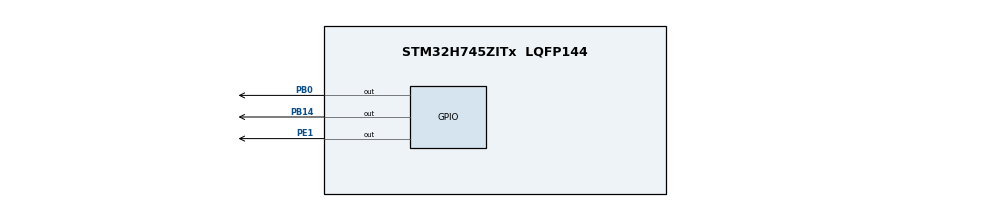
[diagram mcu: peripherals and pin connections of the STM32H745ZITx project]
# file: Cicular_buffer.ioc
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CortexM4.IPs=BDMA,CORTEX_M4\:I,DEBUG,DMA,FATFS_M4\:I,FREERTOS_M4\:I,IWDG2\:I,MDMA,NVIC2\:I,OPENAMP_M4\:I,PDM2PCM_M4\:I,PWR,RCC,RESMGR_UTILITY,SYS_M4\:I,USB_DEVICE_M4\:I,USB_HOST_M4\:I,VREFBUF,WWDG2\:I
CortexM7.IPs=BDMA\:I,CORTEX_M7\:I,DEBUG\:I,DMA\:I,FATFS_M7\:I,FREERTOS_M7\:I,IWDG1\:I,MDMA\:I,NVIC1\:I,OPENAMP_M7\:I,PDM2PCM_M7\:I,PWR\:I,RCC\:I,RESMGR_UTILITY\:I,SYS\:I,USB_DEVICE_M7\:I,USB_HOST_M7\:I,VREFBUF\:I,WWDG1\:I,TIM16\:I
CortexM7.Pins=PB0,PB14,PE1
Mcu.Family=STM32H7
Mcu.Name=STM32H745ZITx
Mcu.Package=LQFP144
NVIC1.PriorityGroup=NVIC_PRIORITYGROUP_4
NVIC1.TIM16_IRQn=true\:0\:0\:false\:false\:true\:true\:true
NVIC2.PriorityGroup=NVIC_PRIORITYGROUP_4
PB0.PinAttribute=CortexM7
PB0.Signal=GPIO_Output
PB14.PinAttribute=CortexM7
PB14.Signal=GPIO_Output
PE1.PinAttribute=CortexM7
PE1.Signal=GPIO_Output
PH0-OSC_IN\ (PH0).Mode=HSE-External-Oscillator
PH0-OSC_IN\ (PH0).PinAttribute=CortexM7
PH0-OSC_IN\ (PH0).Signal=RCC_OSC_IN
PH1-OSC_OUT\ (PH1).Mode=HSE-External-Oscillator
PH1-OSC_OUT\ (PH1).PinAttribute=CortexM7
PH1-OSC_OUT\ (PH1).Signal=RCC_OSC_OUT
ProjectManager.HeapSize=M4-0x200,M7-0x200
ProjectManager.StackSize=M4-0x400,M7-0x400
ProjectManager.TargetToolchain=STM32CubeIDE
RCC.ADCFreq_Value=129000000
RCC.APB1Freq_Value=90000000
RCC.APB2Freq_Value=90000000
RCC.APB3Freq_Value=90000000
RCC.APB4Freq_Value=90000000
RCC.CortexFreq_Value=180000000
RCC.DIVM1=4
RCC.DIVN1=22
RCC.HCLKFreq_Value=90000000
RCC.HPRE=RCC_HCLK_DIV2
RCC.HSE_VALUE=25000000
RCC.PLL1_VCI_Range-AdvancedSettings=RCC_PLL1VCIRANGE_0
RCC.PLL2FRACN=0
RCC.PLL2_VCI_Range-AdvancedSettings=RCC_PLL2VCIRANGE_0
RCC.PLL2_VCO_SEL-AdvancedSettings=RCC_PLL2VCOMEDIUM
RCC.PLL3FRACN=0
RCC.PLLFRACN=4096
RCC.SYSCLKFreq_VALUE=180000000
RCC.SYSCLKSource=RCC_SYSCLKSOURCE_PLLCLK
RCC.USBFreq_Value=180000000
SYS.userName=SYS_M7
TIM16.AutoReloadPreload=TIM_AUTORELOAD_PRELOAD_ENABLE
TIM16.Period=65535
TIM16.Prescaler=13800
VP_SYS_M4_VS_Systick.Mode=SysTick
VP_TIM16_VS_ClockSourceINT.Mode=Enable_Timer
board=custom

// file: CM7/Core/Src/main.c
/* USER CODE BEGIN Header */
/**
  ******************************************************************************
  * @file           : main.c
  * @brief          : Main program body
  ******************************************************************************
  * @attention
  *
  * <h2><center>&copy; Copyright (c) 2022 STMicroelectronics.
  * All rights reserved.</center></h2>
  *
  * This software component is licensed by ST under BSD 3-Clause license,
  * the "License"; You may not use this file except in compliance with the
  * License. You may obtain a copy of the License at:
  *                        opensource.org/licenses/BSD-3-Clause
  *
  ******************************************************************************
  */
/* USER CODE END Header */
#include "main.h"
#include"circular_buffer.h"

/* USER CODE BEGIN PD */

#ifndef HSEM_ID_0
#define HSEM_ID_0 (0U) /* HW semaphore 0*/
#endif
/* USER CODE END PD */

TIM_HandleTypeDef htim16;

void SystemClock_Config(void);
static void MX_TIM16_Init(void);
static void MX_GPIO_Init(void);

/* USER CODE BEGIN 0 */
static uint16_t current_time=0, prev_time=0,time;
extern buffer_t  data_node;
/* USER CODE END 0 */

int main(void)
{
/* USER CODE BEGIN Boot_Mode_Sequence_0 */
  int32_t timeout;
/* USER CODE END Boot_Mode_Sequence_0 */

/* USER CODE BEGIN Boot_Mode_Sequence_1 */
  /* Wait until CPU2 boots and enters in stop mode or timeout*/
//  timeout = 0xFFFF;
//  while((__HAL_RCC_GET_FLAG(RCC_FLAG_D2CKRDY) != RESET) && (timeout-- > 0));
//  if ( timeout < 0 )
//  {
//  Error_Handler();
//  }
/* USER CODE END Boot_Mode_Sequence_1 */
  /* MCU Configuration--------------------------------------------------------*/

  /* Reset of all peripherals, Initializes the Flash interface and the Systick. */
  HAL_Init();

  /* Configure the system clock */
  SystemClock_Config();
/* USER CODE BEGIN Boot_Mode_Sequence_2 */
/* When system initialization is finished, Cortex-M7 will release Cortex-M4 by means of
HSEM notification */
/*HW semaphore Clock enable*/
__HAL_RCC_HSEM_CLK_ENABLE();
/*Take HSEM */
HAL_HSEM_FastTake(HSEM_ID_0);
/*Release HSEM in order to notify the CPU2(CM4)*/
HAL_HSEM_Release(HSEM_ID_0,0);
/* wait until CPU2 wakes up from stop mode */
timeout = 0xFFFF;
while((__HAL_RCC_GET_FLAG(RCC_FLAG_D2CKRDY) == RESET) && (timeout-- > 0));
if ( timeout < 0 )
{
Error_Handler();
}
/* USER CODE END Boot_Mode_Sequence_2 */

  /* Initialize all configured peripherals */
  MX_TIM16_Init();
  MX_GPIO_Init();
  buffer_init();
  /* USER CODE BEGIN 2 */
  prev_time=HAL_GetTick();
HAL_TIM_Base_Start_IT(&htim16);
  /* USER CODE END 2 */

  /* Infinite loop */
  while (1)
  {
  }
}

void SystemClock_Config(void)
{
  RCC_OscInitTypeDef RCC_OscInitStruct = {0};
  RCC_ClkInitTypeDef RCC_ClkInitStruct = {0};

  /** Supply configuration update enable
  */
  HAL_PWREx_ConfigSupply(PWR_DIRECT_SMPS_SUPPLY);
  /** Configure the main internal regulator output voltage
  */
  __HAL_PWR_VOLTAGESCALING_CONFIG(PWR_REGULATOR_VOLTAGE_SCALE3);

  while(!__HAL_PWR_GET_FLAG(PWR_FLAG_VOSRDY)) {}
  /** Initializes the RCC Oscillators according to the specified parameters
  * in the RCC_OscInitTypeDef structure.
  */
  RCC_OscInitStruct.OscillatorType = RCC_OSCILLATORTYPE_HSI;
  RCC_OscInitStruct.HSIState = RCC_HSI_DIV1;
  RCC_OscInitStruct.HSICalibrationValue = RCC_HSICALIBRATION_DEFAULT;
  RCC_OscInitStruct.PLL.PLLState = RCC_PLL_ON;
  RCC_OscInitStruct.PLL.PLLSource = RCC_PLLSOURCE_HSI;
  RCC_OscInitStruct.PLL.PLLM = 4;
  RCC_OscInitStruct.PLL.PLLN = 22;
  RCC_OscInitStruct.PLL.PLLP = 2;
  RCC_OscInitStruct.PLL.PLLQ = 2;
  RCC_OscInitStruct.PLL.PLLR = 2;
  RCC_OscInitStruct.PLL.PLLRGE = RCC_PLL1VCIRANGE_3;
  RCC_OscInitStruct.PLL.PLLVCOSEL = RCC_PLL1VCOWIDE;
  RCC_OscInitStruct.PLL.PLLFRACN = 4096;
  if (HAL_RCC_OscConfig(&RCC_OscInitStruct) != HAL_OK)
  {
    Error_Handler();
  }
  /** Initializes the CPU, AHB and APB buses clocks
  */
  RCC_ClkInitStruct.ClockType = RCC_CLOCKTYPE_HCLK|RCC_CLOCKTYPE_SYSCLK
                              |RCC_CLOCKTYPE_PCLK1|RCC_CLOCKTYPE_PCLK2
                              |RCC_CLOCKTYPE_D3PCLK1|RCC_CLOCKTYPE_D1PCLK1;
  RCC_ClkInitStruct.SYSCLKSource = RCC_SYSCLKSOURCE_PLLCLK;
  RCC_ClkInitStruct.SYSCLKDivider = RCC_SYSCLK_DIV1;
  RCC_ClkInitStruct.AHBCLKDivider = RCC_HCLK_DIV2;
  RCC_ClkInitStruct.APB3CLKDivider = RCC_APB3_DIV1;
  RCC_ClkInitStruct.APB1CLKDivider = RCC_APB1_DIV1;
  RCC_ClkInitStruct.APB2CLKDivider = RCC_APB2_DIV1;
  RCC_ClkInitStruct.APB4CLKDivider = RCC_APB4_DIV1;

  if (HAL_RCC_ClockConfig(&RCC_ClkInitStruct, FLASH_LATENCY_1) != HAL_OK)
  {
    Error_Handler();
  }
}

static void MX_TIM16_Init(void)
{

  htim16.Instance = TIM16;
  htim16.Init.Prescaler = 13800;
  htim16.Init.CounterMode = TIM_COUNTERMODE_UP;
  htim16.Init.Period = 65535;
  htim16.Init.ClockDivision = TIM_CLOCKDIVISION_DIV1;
  htim16.Init.RepetitionCounter = 0;
  htim16.Init.AutoReloadPreload = TIM_AUTORELOAD_PRELOAD_ENABLE;
  if (HAL_TIM_Base_Init(&htim16) != HAL_OK)
  {
    Error_Handler();
  }

}

static void MX_GPIO_Init(void)
{
  GPIO_InitTypeDef GPIO_InitStruct = {0};

  /* GPIO Ports Clock Enable */
  __HAL_RCC_GPIOH_CLK_ENABLE();
  __HAL_RCC_GPIOB_CLK_ENABLE();
  __HAL_RCC_GPIOE_CLK_ENABLE();

  /*Configure GPIO pin Output Level */
  HAL_GPIO_WritePin(GPIOB, GPIO_PIN_0|GPIO_PIN_14, GPIO_PIN_RESET);

  /*Configure GPIO pin Output Level */
  HAL_GPIO_WritePin(GPIOE, GPIO_PIN_1, GPIO_PIN_RESET);

  /*Configure GPIO pins : PB0 PB14 */
  GPIO_InitStruct.Pin = GPIO_PIN_0|GPIO_PIN_14;
  GPIO_InitStruct.Mode = GPIO_MODE_OUTPUT_PP;
  GPIO_InitStruct.Pull = GPIO_NOPULL;
  GPIO_InitStruct.Speed = GPIO_SPEED_FREQ_LOW;
  HAL_GPIO_Init(GPIOB, &GPIO_InitStruct);

  /*Configure GPIO pin : PE1 */
  GPIO_InitStruct.Pin = GPIO_PIN_1;
  GPIO_InitStruct.Mode = GPIO_MODE_OUTPUT_PP;
  GPIO_InitStruct.Pull = GPIO_NOPULL;
  GPIO_InitStruct.Speed = GPIO_SPEED_FREQ_LOW;
  HAL_GPIO_Init(GPIOE, &GPIO_InitStruct);

}

/* USER CODE BEGIN 4 */
 void HAL_TIM_PeriodElapsedCallback(TIM_HandleTypeDef *htim)
{
	 static uint8_t temp=0;

	 if(data_node.flag==true)
	 {
		 read_buffer();
	 }

	 else
	 {
		 write_buffer(temp);
	 }

	 temp++;
}
/* USER CODE END 4 */

void Error_Handler(void)
{
  __disable_irq();
  while (1)
  {
  }
}

/************************ (C) COPYRIGHT STMicroelectronics *****END OF FILE****/
